# PRU_ICSSG0_PR1_PDSP0_IRAM_local register map
Vendor: Texas Instruments
Peripheral module from a debugger description file (folder J7ES).
Registers are 32-bit, read-write, reset 0x0 unless marked. A register's access mark holds for its fields unless they carry their own. Offsets are as the file gives them; lines under a group give offsets from that group; [hi:lo] are bit positions; {n}, {i} and the like mark numbered series; 'fields as' and 'values as' point back to an identical list; <NAME> marks a mode.

## PRU_ICSSG0_PR1_PDSP0_IRAM
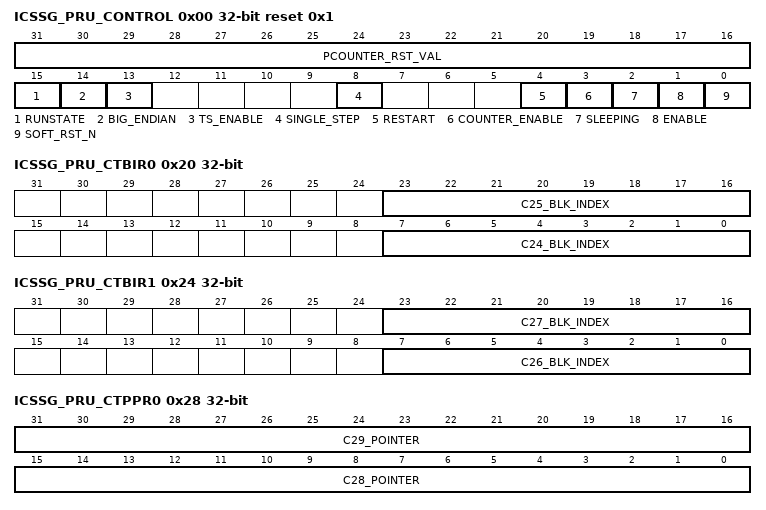
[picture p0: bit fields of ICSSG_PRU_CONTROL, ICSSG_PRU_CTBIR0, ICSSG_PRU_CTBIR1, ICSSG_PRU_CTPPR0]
0x00 ICSSG_PRU_CONTROL access per field reset 0x1 — PRU Control Register.
  [31:16] PCOUNTER_RST_VAL rw — Program Counter Reset Value: This field controls the address where the PRU will start executing code from after it is taken out of reset.
  [15] RUNSTATE ro — Run State: This bit indicates whether the PRU is currently executing an instruction or is halted.
  [14] BIG_ENDIAN ro — Big Endian Input State: This bit indicates the current state of the big_endian input. This bit is used by an external debug agent to interpret the register file contents appropriately.
  [13] TS_ENABLE ro — Task Swapping Enable: This bit indicates the current state of the internal task swapping enable flag. When this bit is clear, the PRU will ignore requests which are presented on the Task Swap Request interface. When this bit is set, the PRU will gracefully complete any multi-cycle instruction and will then issue an XCHG instruction using the 22 LSBs as provided on the task swap request interface.
  [8] SINGLE_STEP rw — Single Step Enable: This bit controls whether or not the PRU will only execute a single instruction when enabled.
  [4] RESTART rw — PRU Restart: Causes PRU to stop current operation gracefully and return to the PC reset value and begin operation – only flags, PC, and ALU registers are cleared.
  [3] COUNTER_ENABLE rw — PRU Cycle Counter Enable: Enables PRU cycle counters.
  [2] SLEEPING rw — PRU Sleep Indicator: This bit indicates whether or not the PRU is currently asleep.
  [1] ENABLE rw — Processor Enable: This bit controls whether or not the PRU is allowed to fetch new instructions.If this bit is de-asserted while the PRU is currently running and has completed the initial cycle of a multi-cycle instruction (LBxO,SBxO,SCAN, etc.), the current instruction will be allowed to complete before the PRU pauses execution. Otherwise, the PRU will halt immediately. Because of the unpredictability timing sensitivity of the instruction execution loop, this bit is not a reliable indication of whether or not the PRU is currently running. The [15]RUNSTATE bit should be consulted for an absolute indication of the run state of the core.When the PRU is halted, its internal state remains coherent therefore this bit can be reasserted without issuing a software reset and the PRU will resume processing exactly where it left off in the instruction stream.
  [0] SOFT_RST_N rw — Soft Reset: When this bit is cleared, the PRU will be reset. This bit is set back to 1h on the next cycle after it has been cleared.
0x04 ICSSG_PRU_STATUS ro — PRU Status Register.
  [15:0] PCOUNTER — Program Counter: This field is a registered (1 cycle delayed) reflection of the PRU program counter.
0x08 ICSSG_PRU_WAKEUP_EN — PRU Wakeup Enable Register.
  [31:0] BITWISE_ENABLES — Wakeup Enables: This field is ANDed with the incoming R31 status inputs (whose bit positions were specified in the stmap parameter) to produce a vector which is unary ORed to produce the status_wakeup source for the core.Setting any bit in this vector will allow the corresponding status input to wake up the core when it is asserted high. The PRU should set this enable vector prior to executing a SLP (sleep) instruction to ensure that the desired sources can wake up the core.
0x0C ICSSG_PRU_CYCLE — PRU Cycle Count. This register counts the number of cycles for which the PRU has been enabled.
  [31:0] CYCLECOUNT — This value is incremented by 1 for every cycle during which the PRU is enabled and the counter is enabled (both bits [1]ENABLE and [3]COUNTER_ENABLE set in theCounter clears the [3]COUNTER_ENABLE bit in the
0x10 ICSSG_PRU_STALL ro — PRU Stall Count Register. This register counts the number of cycles for which the PRU has been enabled, but unable to fetch a new instruction. It is linked to the Cycle Count Register (, offset: 0Ch) such that this register reflects the stall cycles measured over the same cycles as counted by the cycle count register. Thus the value of this register is always less than or equal to cycle count.
  [31:0] STALLCOUNT — This value is incremented by 1 for every cycle during which the PRU is enabled and the counter is enabled (both bits [1]ENABLE and [3]COUNTER_ENABLE set in theCounting halts while the PRU is disabled or the counter is disabled, and resumes when re-eneabled. The register can be read at any time. The register is cleared when PRU Cycle Count Register (
0x20 ICSSG_PRU_CTBIR0 access per field — Constant Table Block Index Register 0. This register is used to set the block indices which are used to modify entries 24 and 25 in the PRU Constant Table. This register can be written by the PRU whenever it needs to change to a new base pointer for a block in the State Scratchpad RAM. This function is useful since the PRU is often processing multiple processing threads which require it to change contexts. The PRU can use this register to avoid requiring excessive amounts of code for repetitive context switching.
  [23:16] C25_BLK_INDEX rw — PRU Constant Entry 25 Block Index: This field sets the value that will appear in bits 15:8 of entry 25 in the PRU Constant Table.This field while always present is only used if the ctreg_cnt configuration value is less than 26.
  [7:0] C24_BLK_INDEX rw — PRU Constant Entry 24 Block Index: This field sets the value that will appear in bits 15:8 of entry 24 in the PRU Constant Table.This field while always present is only used if the ctreg_cnt configuration value is less than 25.
0x24 ICSSG_PRU_CTBIR1 access per field — Constant Table Block Index Register 1. This register is used to set the block indices which are used to modify entries 26 and 27 in the PRU Constant Table. This register can be written by the PRU whenever it needs to change to a new base pointer for a block in the State Scratchpad RAM. This function is useful since the PRU is often processing multiple processing threads which require it to change contexts. The PRU can use this register to avoid requiring excessive amounts of code for repetitive context switching.
  [23:16] C27_BLK_INDEX rw — PRU Constant Entry 27 Block Index: This field sets the value that will appear in bits 15:8 of entry 27 in the PRU Constant Table.This field while always present is only used if the ctreg_cnt configuration value is less than 28.
  [7:0] C26_BLK_INDEX rw — PRU Constant Entry 26 Block Index: This field sets the value that will appear in bits 15:8 of entry 26 in the PRU Constant Table.This field while always present is only used if the ctreg_cnt configuration value is less than 27.
0x28 ICSSG_PRU_CTPPR0 — Constant Table Programmable Pointer Register 0. This register allows the PRU to set up the 256-byte page index for entries 28 and 29 in the PRU Constant Table which serve as general purpose pointers which can be configured to point to any locations inside the session router address map. This register is useful when the PRU needs to frequently access certain structures inside the session router address space whose locations are not hard coded such as tables in scratchpad memory.
  [31:16] C29_POINTER — PRU Constant Entry 29 Pointer: This field sets the value that will appear in bits [23-8] of entry 29 in the PRU Constant Table.This field while always present is only used if the ctreg_cnt configuration value is less than 30.
  [15:0] C28_POINTER — PRU Constant Entry 28 Pointer: This field sets the value that will appear in bits [23-8] of entry 28 in the PRU Constant Table.This field while always present is only used if the ctreg_cnt configuration value is less than 29.
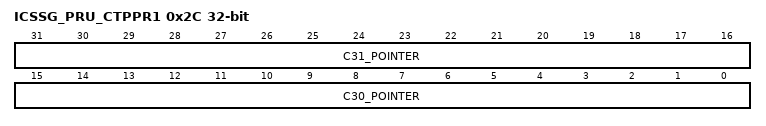
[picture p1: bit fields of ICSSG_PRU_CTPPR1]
0x2C ICSSG_PRU_CTPPR1 — Constant Table Programmable Pointer Register 1. This register functions the same as the PRU Constant Table Programmable Pointer Register 0 but allows the PRU to control entries 30 and 31 in the PRU Constant Table.
  [31:16] C31_POINTER — PRU Constant Entry 31 Pointer: This field sets the value that will appear in bits [23-8] of entry 31 in the PRU Constant Table.This field while always present is only used if the ctreg_cnt configuration value is less than 32.
  [15:0] C30_POINTER — PRU Constant Entry 30 Pointer: This field sets the value that will appear in bits [23-8] of entry 30 in the PRU Constant Table.This field while always present is only used if the ctreg_cnt configuration value is less than 31.
